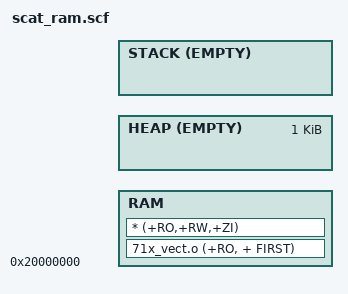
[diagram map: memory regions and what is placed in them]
;******************** (C) COPYRIGHT 2006 STMicroelectronics ********************
;* File Name          : scat.scf
;* Author             : MCD Application Team
;* Date First Issued  : 10/01/2006 : V1.0
;* Description        : RAM scatter file 
;********************************************************************************
;* History:
;* 10/01/2006 : V1.0
;*******************************************************************************
; THE PRESENT SOFTWARE WHICH IS FOR GUIDANCE ONLY AIMS AT PROVIDING CUSTOMERS WITH
; CODING INFORMATION REGARDING THEIR PRODUCTS IN ORDER FOR THEM TO SAVE TIME.
; AS A RESULT, STMICROELECTRONICS SHALL NOT BE HELD LIABLE FOR ANY DIRECT, INDIRECT
; OR CONSEQUENTIAL DAMAGES WITH RESPECT TO ANY CLAIMS ARISING FROM THE CONTENT
; OF SUCH SOFTWARE AND/OR THE USE MADE BY CUSTOMERS OF THE CODING INFORMATION
; CONTAINED HEREIN IN CONNECTION WITH THEIR PRODUCTS.
;*******************************************************************************/

USER_MODE  0x20000000  0x10000
{
    RAM 0x20000000
    {
        71x_vect.o (+RO, + FIRST)
        * (+RO,+RW,+ZI)
       
    }

    ; Heap will grow just above ZI region :
    ; This Symbol is exported to "71x_init.s" file

    HEAP +0 EMPTY 0x400
    {	
    }

    ; Stack Base address exported to "71x_init.s" file ( Top of SRAM )

    STACK 0x2000F000 EMPTY -0x0
    {
    }

}
